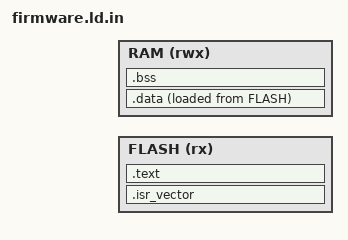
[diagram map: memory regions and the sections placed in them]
ENTRY(Reset_Handler)

MEMORY
{
  FLASH (rx) : ORIGIN = @FLASH_BASE@, LENGTH = @FLASH_SIZE@
  RAM  (rwx) : ORIGIN = @RAM_BASE@,   LENGTH = @RAM_SIZE@
}

_estack = ORIGIN(RAM) + LENGTH(RAM);

SECTIONS
{
  .isr_vector : { KEEP(*(.isr_vector)) } > FLASH
  .text : {
    *(.text) *(.text*)
    *(.rodata) *(.rodata*)
    . = ALIGN(4);
    _etext = .;
  } > FLASH
  _sidata = LOADADDR(.data);
  .data : {
    . = ALIGN(4);
    _sdata = .;
    *(.data) *(.data*)
    . = ALIGN(4);
    _edata = .;
  } > RAM AT > FLASH
  .bss : {
    . = ALIGN(4);
    _sbss = .;
    *(.bss) *(.bss*) *(COMMON)
    . = ALIGN(4);
    _ebss = .;
  } > RAM
  /DISCARD/ : { *(.ARM.exidx*) *(.comment) }
}
